AUTOSAR XML (schema 4-2-2)
package /STELLANTIS/EPT/ASWCs
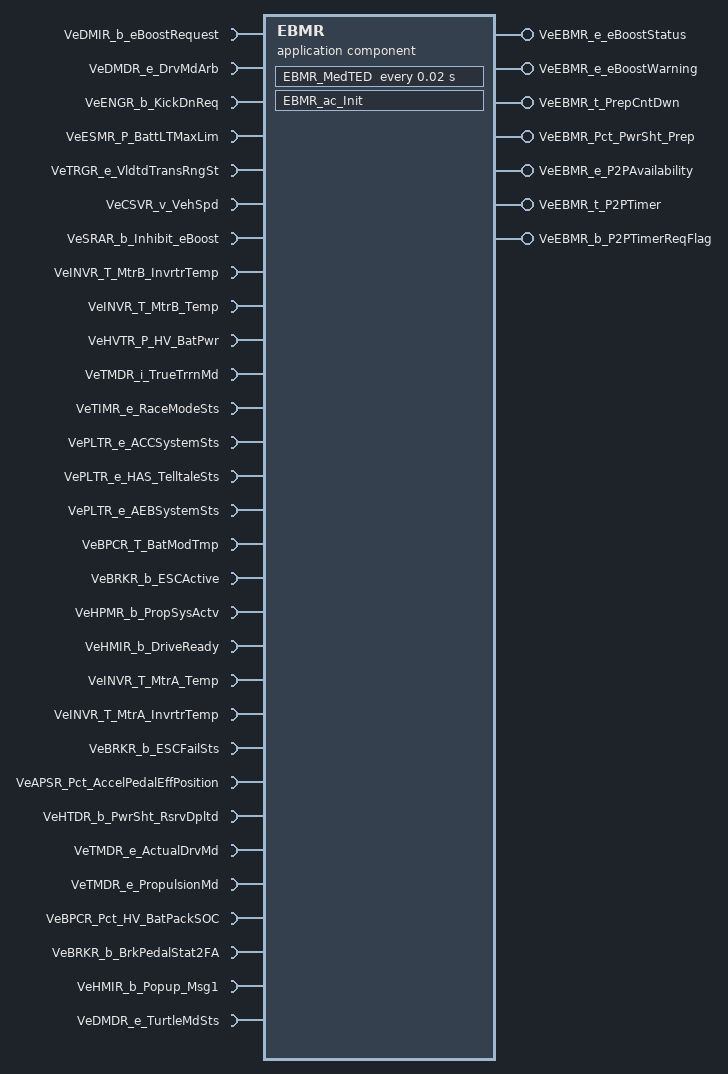
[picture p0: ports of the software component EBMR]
  application sw component type EBMR
    30 x require port:
      VeDMIR_b_eBoostRequest: variation-point={short-label=vpVeDMIR_b_eBoostRequest, sw-syscond=1}, nonqueued-receiver-com-spec{data-element=Value, init-value=0}, required-interface=VeDMIR_b_eBoostRequest
      VeDMDR_e_DrvMdArb: variation-point={short-label=vpVeDMDR_e_DrvMdArb, sw-syscond=1}, nonqueued-receiver-com-spec{data-element=Value, init-value=CeDMDR_e_NoDrvMd}, required-interface=VeDMDR_e_DrvMdArb
      VeENGR_b_KickDnReq: variation-point={short-label=vpVeENGR_b_KickDnReq, sw-syscond=1}, nonqueued-receiver-com-spec{data-element=Value, init-value=0}, required-interface=VeENGR_b_KickDnReq
      VeESMR_P_BattLTMaxLim: variation-point={short-label=vpVeESMR_P_BattLTMaxLim, sw-syscond=1}, nonqueued-receiver-com-spec{data-element=Value, init-value=0}, required-interface=VeESMR_P_BattLTMaxLim
      VeTRGR_e_VldtdTransRngSt: variation-point={short-label=vpVeTRGR_e_VldtdTransRngSt, sw-syscond=1}, nonqueued-receiver-com-spec{data-element=Value, init-value=CeTRGR_e_NoSelectionAvailable}, required-interface=VeTRGR_e_VldtdTransRngSt
      VeCSVR_v_VehSpd: variation-point={short-label=vpVeCSVR_v_VehSpd, sw-syscond=1}, nonqueued-receiver-com-spec{data-element=Value, init-value=0}, required-interface=VeCSVR_v_VehSpd
      VeSRAR_b_Inhibit_eBoost: variation-point={short-label=vpVeSRAR_b_Inhibit_eBoost, sw-syscond=1}, nonqueued-receiver-com-spec{data-element=Value, init-value=0}, required-interface=VeSRAR_b_Inhibit_eBoost
      VeINVR_T_MtrB_InvrtrTemp: variation-point={short-label=vpVeINVR_T_MtrB_InvrtrTemp, sw-syscond=1}, nonqueued-receiver-com-spec{data-element=Value, init-value=0}, required-interface=VeINVR_T_MtrB_InvrtrTemp
      VeINVR_T_MtrB_Temp: variation-point={short-label=vpVeINVR_T_MtrB_Temp, sw-syscond=1}, nonqueued-receiver-com-spec{data-element=Value, init-value=0}, required-interface=VeINVR_T_MtrB_Temp
      VeHVTR_P_HV_BatPwr: variation-point={short-label=vpVeHVTR_P_HV_BatPwr, sw-syscond=1}, nonqueued-receiver-com-spec{data-element=Value, init-value=0}, required-interface=VeHVTR_P_HV_BatPwr
      VeTMDR_i_TrueTrrnMd: variation-point={short-label=vpVeTMDR_i_TrueTrrnMd, sw-syscond=1}, nonqueued-receiver-com-spec{data-element=Value, init-value=0}, required-interface=VeTMDR_i_TrueTrrnMd
      VeTIMR_e_RaceModeSts: variation-point={short-label=vpVeTIMR_e_RaceModeSts, sw-syscond=1}, nonqueued-receiver-com-spec{data-element=Value, init-value=CeTIMR_e_RaceMode_Off}, required-interface=VeTIMR_e_RaceModeSts
      VePLTR_e_ACCSystemSts: variation-point={short-label=vpVePLTR_e_ACCSystemSts, sw-syscond=1}, nonqueued-receiver-com-spec{data-element=Value, init-value=CePLTR_e_Off}, required-interface=VePLTR_e_ACCSystemSts
      VePLTR_e_HAS_TelltaleSts: variation-point={short-label=vpVePLTR_e_HAS_TelltaleSts, sw-syscond=1}, nonqueued-receiver-com-spec{data-element=Value, init-value=CePLTR_e_HAS_TelltaleSts_OFF}, required-interface=VePLTR_e_HAS_TelltaleSts
      VePLTR_e_AEBSystemSts: variation-point={short-label=vpVePLTR_e_AEBSystemSts, sw-syscond=1}, nonqueued-receiver-com-spec{data-element=Value, init-value=CePLTR_e_FCW_Off}, required-interface=VePLTR_e_AEBSystemSts
      VeBPCR_T_BatModTmp: variation-point={short-label=vpVeBPCR_T_BatModTmp, sw-syscond=1}, nonqueued-receiver-com-spec{data-element=Value, init-value=0}, required-interface=VeBPCR_T_BatModTmp
      VeBRKR_b_ESCActive: variation-point={short-label=vpVeBRKR_b_ESCActive, sw-syscond=1}, nonqueued-receiver-com-spec{data-element=Value, init-value=0}, required-interface=VeBRKR_b_ESCActive
      VeHPMR_b_PropSysActv: variation-point={short-label=vpVeHPMR_b_PropSysActv, sw-syscond=1}, nonqueued-receiver-com-spec{data-element=Value, init-value=0}, required-interface=VeHPMR_b_PropSysActv
      VeHMIR_b_DriveReady: variation-point={short-label=vpVeHMIR_b_DriveReady, sw-syscond=1}, nonqueued-receiver-com-spec{data-element=Value, init-value=0}, required-interface=VeHMIR_b_DriveReady
      VeINVR_T_MtrA_Temp: variation-point={short-label=vpVeINVR_T_MtrA_Temp, sw-syscond=1}, nonqueued-receiver-com-spec{data-element=Value, init-value=0}, required-interface=VeINVR_T_MtrA_Temp
      VeINVR_T_MtrA_InvrtrTemp: variation-point={short-label=vpVeINVR_T_MtrA_InvrtrTemp, sw-syscond=1}, nonqueued-receiver-com-spec{data-element=Value, init-value=0}, required-interface=VeINVR_T_MtrA_InvrtrTemp
      VeBRKR_b_ESCFailSts: variation-point={short-label=vpVeBRKR_b_ESCFailSts, sw-syscond=1}, nonqueued-receiver-com-spec{data-element=Value, init-value=0}, required-interface=VeBRKR_b_ESCFailSts
      VeAPSR_Pct_AccelPedalEffPosition: variation-point={short-label=vpVeAPSR_Pct_AccelPedalEffPosition, sw-syscond=1}, nonqueued-receiver-com-spec{data-element=Value, init-value=0}, required-interface=VeAPSR_Pct_AccelPedalEffPosition
      VeHTDR_b_PwrSht_RsrvDpltd: variation-point={short-label=vpVeHTDR_b_PwrSht_RsrvDpltd, sw-syscond=1}, nonqueued-receiver-com-spec{data-element=Value, init-value=0}, required-interface=VeHTDR_b_PwrSht_RsrvDpltd
      VeTMDR_e_ActualDrvMd: variation-point={short-label=vpVeTMDR_e_ActualDrvMd, sw-syscond=1}, nonqueued-receiver-com-spec{data-element=Value, init-value=CeTMDR_e_NotDefine}, required-interface=VeTMDR_e_ActualDrvMd
      VeTMDR_e_PropulsionMd: variation-point={short-label=vpVeTMDR_e_PropulsionMd, sw-syscond=1}, nonqueued-receiver-com-spec{data-element=Value, init-value=CeTMDR_e_NotDefine}, required-interface=VeTMDR_e_PropulsionMd
      VeBPCR_Pct_HV_BatPackSOC: variation-point={short-label=vpVeBPCR_Pct_HV_BatPackSOC, sw-syscond=1}, nonqueued-receiver-com-spec{data-element=Value, init-value=0}, required-interface=VeBPCR_Pct_HV_BatPackSOC
      VeBRKR_b_BrkPedalStat2FA: variation-point={short-label=vpVeBRKR_b_BrkPedalStat2FA, sw-syscond=1}, nonqueued-receiver-com-spec{data-element=Value, init-value=0}, required-interface=VeBRKR_b_BrkPedalStat2FA
      VeHMIR_b_Popup_Msg1: variation-point={short-label=vpVeHMIR_b_Popup_Msg1, sw-syscond=1}, nonqueued-receiver-com-spec{data-element=Value, init-value=0}, required-interface=VeHMIR_b_Popup_Msg1
      VeDMDR_e_TurtleMdSts: variation-point={short-label=vpVeDMDR_e_TurtleMdSts, sw-syscond=1}, nonqueued-receiver-com-spec{data-element=Value, init-value=CeDMDR_e_No_Turtle_Mode}, required-interface=VeDMDR_e_TurtleMdSts
    7 x provide port:
      VeEBMR_e_eBoostStatus: nonqueued-sender-com-spec{data-element=Value, init-value=CeEBMR_e_eBoostOFF}, provided-interface=VeEBMR_e_eBoostStatus
      VeEBMR_e_eBoostWarning: nonqueued-sender-com-spec{data-element=Value, init-value=CeEBMR_e_DeactivatedESCOff}, provided-interface=VeEBMR_e_eBoostWarning
      VeEBMR_t_PrepCntDwn: nonqueued-sender-com-spec{data-element=Value, init-value=0}, provided-interface=VeEBMR_t_PrepCntDwn
      VeEBMR_Pct_PwrSht_Prep: nonqueued-sender-com-spec{data-element=Value, init-value=0}, provided-interface=VeEBMR_Pct_PwrSht_Prep
      VeEBMR_e_P2PAvailability: nonqueued-sender-com-spec{data-element=Value, init-value=0}, provided-interface=VeEBMR_e_P2PAvailability
      VeEBMR_t_P2PTimer: nonqueued-sender-com-spec{data-element=Value, init-value=0}, provided-interface=VeEBMR_t_P2PTimer
      VeEBMR_b_P2PTimerReqFlag: nonqueued-sender-com-spec{data-element=Value, init-value=0}, provided-interface=VeEBMR_b_P2PTimerReqFlag
    behavior IB_EBMR: data-type-mapping=msADTtoIDTMapping, handle-termination-and-restart=NO-SUPPORT, included-data-type-set=data-type=TeEBMR_e_PtoPAvail
      timing event Event_MedTED: start-on-event=EBMR_MedTED, period=0.02
      init event Event_EBMR_ac_Init: start-on-event=EBMR_ac_Init
      runnable EBMR_ac_Init
        data-send-points:
          access OUT_VeEBMR_e_eBoostStatus_Value: accessed-variable=VeEBMR_e_eBoostStatus.Value
          access OUT_VeEBMR_e_eBoostWarning_Value: accessed-variable=VeEBMR_e_eBoostWarning.Value
          access OUT_VeEBMR_e_P2PAvailability_Value: accessed-variable=VeEBMR_e_P2PAvailability.Value
      runnable EBMR_MedTED: variation-point={short-label=vpEBMR_MedTED, sw-syscond=1}
        data-receive-point-by-arguments:
          30 x access:
            IN_VeAPSR_Pct_AccelPedalEffPosition_Value: accessed-variable=VeAPSR_Pct_AccelPedalEffPosition.Value, variation-point={short-label=vpIN_VeAPSR_Pct_AccelPedalEffPosition_Value, sw-syscond=1}
            IN_VeBPCR_Pct_HV_BatPackSOC_Value: accessed-variable=VeBPCR_Pct_HV_BatPackSOC.Value, variation-point={short-label=vpIN_VeBPCR_Pct_HV_BatPackSOC_Value, sw-syscond=1}
            IN_VeBPCR_T_BatModTmp_Value: accessed-variable=VeBPCR_T_BatModTmp.Value, variation-point={short-label=vpIN_VeBPCR_T_BatModTmp_Value, sw-syscond=1}
            IN_VeBRKR_b_BrkPedalStat2FA_Value: accessed-variable=VeBRKR_b_BrkPedalStat2FA.Value, variation-point={short-label=vpIN_VeBRKR_b_BrkPedalStat2FA_Value, sw-syscond=1}
            IN_VeBRKR_b_ESCActive_Value: accessed-variable=VeBRKR_b_ESCActive.Value, variation-point={short-label=vpIN_VeBRKR_b_ESCActive_Value, sw-syscond=1}
            IN_VeBRKR_b_ESCFailSts_Value: accessed-variable=VeBRKR_b_ESCFailSts.Value, variation-point={short-label=vpIN_VeBRKR_b_ESCFailSts_Value, sw-syscond=1}
            IN_VeCSVR_v_VehSpd_Value: accessed-variable=VeCSVR_v_VehSpd.Value, variation-point={short-label=vpIN_VeCSVR_v_VehSpd_Value, sw-syscond=1}
            IN_VeDMDR_e_DrvMdArb_Value: accessed-variable=VeDMDR_e_DrvMdArb.Value, variation-point={short-label=vpIN_VeDMDR_e_DrvMdArb_Value, sw-syscond=1}
            IN_VeDMDR_e_TurtleMdSts_Value: accessed-variable=VeDMDR_e_TurtleMdSts.Value, variation-point={short-label=vpIN_VeDMDR_e_TurtleMdSts_Value, sw-syscond=1}
            IN_VeDMIR_b_eBoostRequest_Value: accessed-variable=VeDMIR_b_eBoostRequest.Value, variation-point={short-label=vpIN_VeDMIR_b_eBoostRequest_Value, sw-syscond=1}
            IN_VeENGR_b_KickDnReq_Value: accessed-variable=VeENGR_b_KickDnReq.Value, variation-point={short-label=vpIN_VeENGR_b_KickDnReq_Value, sw-syscond=1}
            IN_VeESMR_P_BattLTMaxLim_Value: accessed-variable=VeESMR_P_BattLTMaxLim.Value, variation-point={short-label=vpIN_VeESMR_P_BattLTMaxLim_Value, sw-syscond=1}
            IN_VeHMIR_b_DriveReady_Value: accessed-variable=VeHMIR_b_DriveReady.Value, variation-point={short-label=vpIN_VeHMIR_b_DriveReady_Value, sw-syscond=1}
            IN_VeHMIR_b_Popup_Msg1_Value: accessed-variable=VeHMIR_b_Popup_Msg1.Value, variation-point={short-label=vpIN_VeHMIR_b_Popup_Msg1_Value, sw-syscond=1}
            IN_VeHPMR_b_PropSysActv_Value: accessed-variable=VeHPMR_b_PropSysActv.Value, variation-point={short-label=vpIN_VeHPMR_b_PropSysActv_Value, sw-syscond=1}
            IN_VeHTDR_b_PwrSht_RsrvDpltd_Value: accessed-variable=VeHTDR_b_PwrSht_RsrvDpltd.Value, variation-point={short-label=vpIN_VeHTDR_b_PwrSht_RsrvDpltd_Value, sw-syscond=1}
            IN_VeHVTR_P_HV_BatPwr_Value: accessed-variable=VeHVTR_P_HV_BatPwr.Value, variation-point={short-label=vpIN_VeHVTR_P_HV_BatPwr_Value, sw-syscond=1}
            IN_VeINVR_T_MtrA_InvrtrTemp_Value: accessed-variable=VeINVR_T_MtrA_InvrtrTemp.Value, variation-point={short-label=vpIN_VeINVR_T_MtrA_InvrtrTemp_Value, sw-syscond=1}
            IN_VeINVR_T_MtrA_Temp_Value: accessed-variable=VeINVR_T_MtrA_Temp.Value, variation-point={short-label=vpIN_VeINVR_T_MtrA_Temp_Value, sw-syscond=1}
            IN_VeINVR_T_MtrB_InvrtrTemp_Value: accessed-variable=VeINVR_T_MtrB_InvrtrTemp.Value, variation-point={short-label=vpIN_VeINVR_T_MtrB_InvrtrTemp_Value, sw-syscond=1}
            IN_VeINVR_T_MtrB_Temp_Value: accessed-variable=VeINVR_T_MtrB_Temp.Value, variation-point={short-label=vpIN_VeINVR_T_MtrB_Temp_Value, sw-syscond=1}
            IN_VePLTR_e_ACCSystemSts_Value: accessed-variable=VePLTR_e_ACCSystemSts.Value, variation-point={short-label=vpIN_VePLTR_e_ACCSystemSts_Value, sw-syscond=1}
            IN_VePLTR_e_AEBSystemSts_Value: accessed-variable=VePLTR_e_AEBSystemSts.Value, variation-point={short-label=vpIN_VePLTR_e_AEBSystemSts_Value, sw-syscond=1}
            IN_VePLTR_e_HAS_TelltaleSts_Value: accessed-variable=VePLTR_e_HAS_TelltaleSts.Value, variation-point={short-label=vpIN_VePLTR_e_HAS_TelltaleSts_Value, sw-syscond=1}
            IN_VeSRAR_b_Inhibit_eBoost_Value: accessed-variable=VeSRAR_b_Inhibit_eBoost.Value, variation-point={short-label=vpIN_VeSRAR_b_Inhibit_eBoost_Value, sw-syscond=1}
            IN_VeTIMR_e_RaceModeSts_Value: accessed-variable=VeTIMR_e_RaceModeSts.Value, variation-point={short-label=vpIN_VeTIMR_e_RaceModeSts_Value, sw-syscond=1}
            IN_VeTMDR_e_ActualDrvMd_Value: accessed-variable=VeTMDR_e_ActualDrvMd.Value, variation-point={short-label=vpIN_VeTMDR_e_ActualDrvMd_Value, sw-syscond=1}
            IN_VeTMDR_e_PropulsionMd_Value: accessed-variable=VeTMDR_e_PropulsionMd.Value, variation-point={short-label=vpIN_VeTMDR_e_PropulsionMd_Value, sw-syscond=1}
            IN_VeTMDR_i_TrueTrrnMd_Value: accessed-variable=VeTMDR_i_TrueTrrnMd.Value, variation-point={short-label=vpIN_VeTMDR_i_TrueTrrnMd_Value, sw-syscond=1}
            IN_VeTRGR_e_VldtdTransRngSt_Value: accessed-variable=VeTRGR_e_VldtdTransRngSt.Value, variation-point={short-label=vpIN_VeTRGR_e_VldtdTransRngSt_Value, sw-syscond=1}
        data-send-points:
          7 x access:
            OUT_VeEBMR_e_eBoostStatus_Value: accessed-variable=VeEBMR_e_eBoostStatus.Value
            OUT_VeEBMR_e_eBoostWarning_Value: accessed-variable=VeEBMR_e_eBoostWarning.Value
            OUT_VeEBMR_t_PrepCntDwn_Value: accessed-variable=VeEBMR_t_PrepCntDwn.Value
            OUT_VeEBMR_Pct_PwrSht_Prep_Value: accessed-variable=VeEBMR_Pct_PwrSht_Prep.Value
            OUT_VeEBMR_e_P2PAvailability_Value: accessed-variable=VeEBMR_e_P2PAvailability.Value
            OUT_VeEBMR_t_P2PTimer_Value: accessed-variable=VeEBMR_t_P2PTimer.Value
            OUT_VeEBMR_b_P2PTimerReqFlag_Value: accessed-variable=VeEBMR_b_P2PTimerReqFlag.Value
      variation point proxy Variant_EBMR_1: category=CONDITION, condition-access=1
      variation point proxy Variant_EBMR_2: category=CONDITION, condition-access=1
